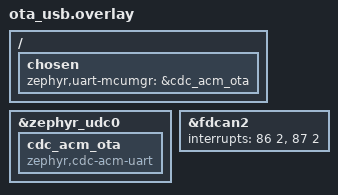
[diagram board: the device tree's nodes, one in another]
/ {
	chosen {
		zephyr,uart-mcumgr = &cdc_acm_ota;
	};
};

&zephyr_udc0 {
	cdc_acm_ota: cdc_acm_ota {
		compatible = "zephyr,cdc-acm-uart";
	};
};

/* FDCAN2 must yield to HRTIM's logical priority 0 control interrupt.
 * Keep normal kernel-aware CAN IRQs; RS485 RX retains its zero-latency IRQ.
 */
&fdcan2 {
	interrupts = <86 2>, <87 2>;
};
